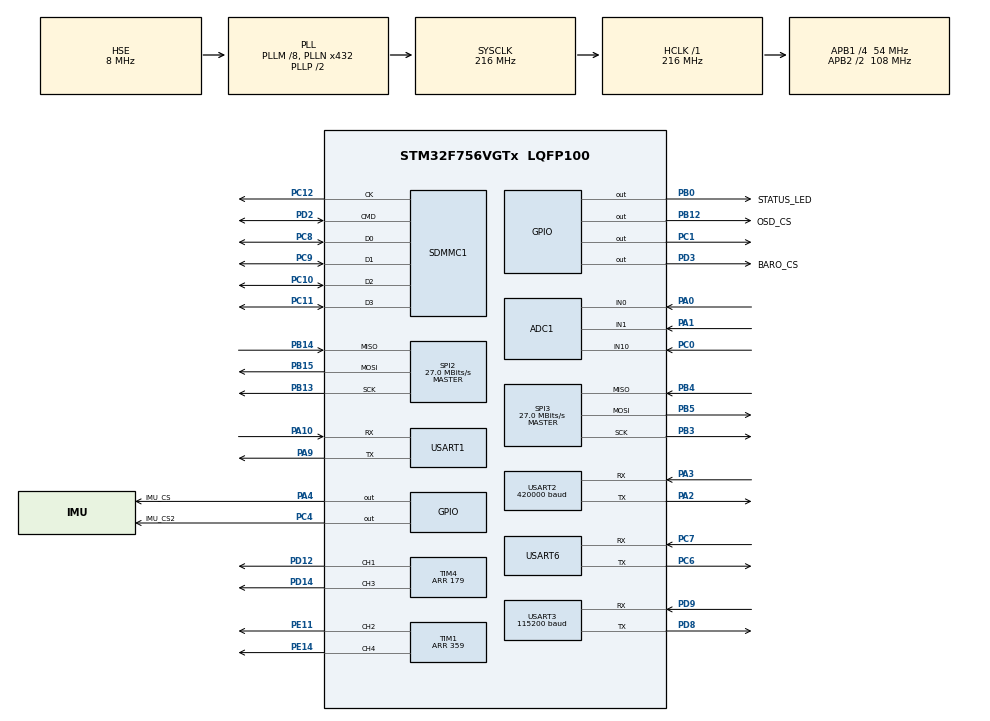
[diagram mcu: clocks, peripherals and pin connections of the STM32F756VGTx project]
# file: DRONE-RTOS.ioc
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ADC1.Channel-0\#ChannelRegularConversion=ADC_CHANNEL_0
ADC1.Channel-1\#ChannelRegularConversion=ADC_CHANNEL_1
ADC1.ContinuousConvMode=ENABLE
ADC1.DMAContinuousRequests=ENABLE
ADC1.DiscontinuousConvMode=DISABLE
ADC1.NbrOfConversion=2
ADC1.NbrOfConversionFlag=1
ADC1.Rank-0\#ChannelRegularConversion=1
ADC1.Rank-1\#ChannelRegularConversion=2
ADC1.SamplingTime-0\#ChannelRegularConversion=ADC_SAMPLETIME_56CYCLES
ADC1.SamplingTime-1\#ChannelRegularConversion=ADC_SAMPLETIME_56CYCLES
ADC1.ScanConvMode=ADC_SCAN_ENABLE
ADC1.master=1
CORTEX_M7.default_mode_Activation=1
Dma.ADC1.3.Direction=DMA_PERIPH_TO_MEMORY
Dma.ADC1.3.FIFOMode=DMA_FIFOMODE_DISABLE
Dma.ADC1.3.Instance=DMA2_Stream0
Dma.ADC1.3.MemDataAlignment=DMA_MDATAALIGN_HALFWORD
Dma.ADC1.3.MemInc=DMA_MINC_ENABLE
Dma.ADC1.3.Mode=DMA_CIRCULAR
Dma.ADC1.3.PeriphDataAlignment=DMA_PDATAALIGN_HALFWORD
Dma.ADC1.3.PeriphInc=DMA_PINC_DISABLE
Dma.ADC1.3.Priority=DMA_PRIORITY_MEDIUM
Dma.Request0=USART2_RX
Dma.Request1=TIM1_CH2
Dma.Request10=USART6_RX
Dma.Request11=TIM4_CH1
Dma.Request2=TIM1_CH4/TRIG/COM
Dma.Request3=ADC1
Dma.Request4=SPI2_RX
Dma.Request5=SPI3_RX
Dma.Request6=TIM4_CH3
Dma.Request7=USART3_RX
Dma.Request8=USART6_TX
Dma.Request9=USART2_TX
Dma.SPI2_RX.4.Direction=DMA_PERIPH_TO_MEMORY
Dma.SPI2_RX.4.FIFOMode=DMA_FIFOMODE_DISABLE
Dma.SPI2_RX.4.Instance=DMA1_Stream3
Dma.SPI2_RX.4.MemDataAlignment=DMA_MDATAALIGN_BYTE
Dma.SPI2_RX.4.MemInc=DMA_MINC_ENABLE
Dma.SPI2_RX.4.Mode=DMA_NORMAL
Dma.SPI2_RX.4.PeriphDataAlignment=DMA_PDATAALIGN_BYTE
Dma.SPI2_RX.4.PeriphInc=DMA_PINC_DISABLE
Dma.SPI2_RX.4.Priority=DMA_PRIORITY_LOW
Dma.SPI3_RX.5.Direction=DMA_PERIPH_TO_MEMORY
Dma.SPI3_RX.5.FIFOMode=DMA_FIFOMODE_DISABLE
Dma.SPI3_RX.5.Instance=DMA1_Stream2
Dma.SPI3_RX.5.MemDataAlignment=DMA_MDATAALIGN_BYTE
Dma.SPI3_RX.5.MemInc=DMA_MINC_ENABLE
Dma.SPI3_RX.5.Mode=DMA_CIRCULAR
Dma.SPI3_RX.5.PeriphDataAlignment=DMA_PDATAALIGN_BYTE
Dma.SPI3_RX.5.PeriphInc=DMA_PINC_DISABLE
Dma.SPI3_RX.5.Priority=DMA_PRIORITY_VERY_HIGH
Dma.TIM1_CH2.1.Direction=DMA_MEMORY_TO_PERIPH
Dma.TIM1_CH2.1.FIFOMode=DMA_FIFOMODE_DISABLE
Dma.TIM1_CH2.1.Instance=DMA2_Stream2
Dma.TIM1_CH2.1.MemDataAlignment=DMA_MDATAALIGN_HALFWORD
Dma.TIM1_CH2.1.MemInc=DMA_MINC_ENABLE
Dma.TIM1_CH2.1.Mode=DMA_NORMAL
Dma.TIM1_CH2.1.PeriphDataAlignment=DMA_PDATAALIGN_HALFWORD
Dma.TIM1_CH2.1.PeriphInc=DMA_PINC_DISABLE
Dma.TIM1_CH2.1.Priority=DMA_PRIORITY_VERY_HIGH
Dma.TIM1_CH4/TRIG/COM.2.Direction=DMA_MEMORY_TO_PERIPH
Dma.TIM1_CH4/TRIG/COM.2.FIFOMode=DMA_FIFOMODE_DISABLE
Dma.TIM1_CH4/TRIG/COM.2.Instance=DMA2_Stream4
Dma.TIM1_CH4/TRIG/COM.2.MemDataAlignment=DMA_MDATAALIGN_HALFWORD
Dma.TIM1_CH4/TRIG/COM.2.MemInc=DMA_MINC_ENABLE
Dma.TIM1_CH4/TRIG/COM.2.Mode=DMA_NORMAL
Dma.TIM1_CH4/TRIG/COM.2.PeriphDataAlignment=DMA_PDATAALIGN_HALFWORD
Dma.TIM1_CH4/TRIG/COM.2.PeriphInc=DMA_PINC_DISABLE
Dma.TIM1_CH4/TRIG/COM.2.Priority=DMA_PRIORITY_VERY_HIGH
Dma.TIM4_CH1.11.Direction=DMA_MEMORY_TO_PERIPH
Dma.TIM4_CH1.11.FIFOMode=DMA_FIFOMODE_DISABLE
Dma.TIM4_CH1.11.Instance=DMA1_Stream0
Dma.TIM4_CH1.11.MemDataAlignment=DMA_MDATAALIGN_HALFWORD
Dma.TIM4_CH1.11.MemInc=DMA_MINC_ENABLE
Dma.TIM4_CH1.11.Mode=DMA_NORMAL
Dma.TIM4_CH1.11.PeriphDataAlignment=DMA_PDATAALIGN_HALFWORD
Dma.TIM4_CH1.11.PeriphInc=DMA_PINC_DISABLE
Dma.TIM4_CH1.11.Priority=DMA_PRIORITY_VERY_HIGH
Dma.TIM4_CH3.6.Direction=DMA_MEMORY_TO_PERIPH
Dma.TIM4_CH3.6.FIFOMode=DMA_FIFOMODE_DISABLE
Dma.TIM4_CH3.6.Instance=DMA1_Stream7
Dma.TIM4_CH3.6.MemDataAlignment=DMA_MDATAALIGN_HALFWORD
Dma.TIM4_CH3.6.MemInc=DMA_MINC_ENABLE
Dma.TIM4_CH3.6.Mode=DMA_NORMAL
Dma.TIM4_CH3.6.PeriphDataAlignment=DMA_PDATAALIGN_HALFWORD
Dma.TIM4_CH3.6.PeriphInc=DMA_PINC_DISABLE
Dma.TIM4_CH3.6.Priority=DMA_PRIORITY_VERY_HIGH
Dma.USART2_RX.0.Direction=DMA_PERIPH_TO_MEMORY
Dma.USART2_RX.0.FIFOMode=DMA_FIFOMODE_DISABLE
Dma.USART2_RX.0.Instance=DMA1_Stream5
Dma.USART2_RX.0.MemDataAlignment=DMA_MDATAALIGN_BYTE
Dma.USART2_RX.0.MemInc=DMA_MINC_ENABLE
Dma.USART2_RX.0.Mode=DMA_CIRCULAR
Dma.USART2_RX.0.PeriphDataAlignment=DMA_PDATAALIGN_BYTE
Dma.USART2_RX.0.PeriphInc=DMA_PINC_DISABLE
Dma.USART2_RX.0.Priority=DMA_PRIORITY_HIGH
Dma.USART2_TX.9.Direction=DMA_MEMORY_TO_PERIPH
Dma.USART2_TX.9.FIFOMode=DMA_FIFOMODE_DISABLE
Dma.USART2_TX.9.Instance=DMA1_Stream6
Dma.USART2_TX.9.MemDataAlignment=DMA_MDATAALIGN_BYTE
Dma.USART2_TX.9.MemInc=DMA_MINC_ENABLE
Dma.USART2_TX.9.Mode=DMA_NORMAL
Dma.USART2_TX.9.PeriphDataAlignment=DMA_PDATAALIGN_BYTE
Dma.USART2_TX.9.PeriphInc=DMA_PINC_DISABLE
Dma.USART2_TX.9.Priority=DMA_PRIORITY_LOW
Dma.USART3_RX.7.Direction=DMA_PERIPH_TO_MEMORY
Dma.USART3_RX.7.FIFOMode=DMA_FIFOMODE_DISABLE
Dma.USART3_RX.7.Instance=DMA1_Stream1
Dma.USART3_RX.7.MemDataAlignment=DMA_MDATAALIGN_BYTE
Dma.USART3_RX.7.MemInc=DMA_MINC_ENABLE
Dma.USART3_RX.7.Mode=DMA_CIRCULAR
Dma.USART3_RX.7.PeriphDataAlignment=DMA_PDATAALIGN_BYTE
Dma.USART3_RX.7.PeriphInc=DMA_PINC_DISABLE
Dma.USART3_RX.7.Priority=DMA_PRIORITY_LOW
Dma.USART6_RX.10.Direction=DMA_PERIPH_TO_MEMORY
Dma.USART6_RX.10.FIFOMode=DMA_FIFOMODE_DISABLE
Dma.USART6_RX.10.Instance=DMA2_Stream1
Dma.USART6_RX.10.MemDataAlignment=DMA_MDATAALIGN_BYTE
Dma.USART6_RX.10.MemInc=DMA_MINC_ENABLE
Dma.USART6_RX.10.Mode=DMA_CIRCULAR
Dma.USART6_RX.10.PeriphDataAlignment=DMA_PDATAALIGN_BYTE
Dma.USART6_RX.10.PeriphInc=DMA_PINC_DISABLE
Dma.USART6_RX.10.Priority=DMA_PRIORITY_MEDIUM
Dma.USART6_TX.8.Direction=DMA_MEMORY_TO_PERIPH
Dma.USART6_TX.8.FIFOMode=DMA_FIFOMODE_DISABLE
Dma.USART6_TX.8.Instance=DMA2_Stream6
Dma.USART6_TX.8.MemDataAlignment=DMA_MDATAALIGN_BYTE
Dma.USART6_TX.8.MemInc=DMA_MINC_ENABLE
Dma.USART6_TX.8.Mode=DMA_NORMAL
Dma.USART6_TX.8.PeriphDataAlignment=DMA_PDATAALIGN_BYTE
Dma.USART6_TX.8.PeriphInc=DMA_PINC_DISABLE
Dma.USART6_TX.8.Priority=DMA_PRIORITY_MEDIUM
Mcu.Family=STM32F7
Mcu.Name=STM32F756VGTx
Mcu.Package=LQFP100
NVIC.DMA1_Stream0_IRQn=true\:0\:0\:false\:false\:true\:false\:true\:true
NVIC.DMA1_Stream1_IRQn=true\:0\:0\:false\:false\:true\:false\:true\:true
NVIC.DMA1_Stream2_IRQn=true\:0\:0\:false\:false\:true\:false\:true\:true
NVIC.DMA1_Stream3_IRQn=true\:0\:0\:false\:false\:true\:false\:true\:true
NVIC.DMA1_Stream5_IRQn=true\:0\:0\:false\:false\:true\:false\:true\:true
NVIC.DMA1_Stream6_IRQn=true\:0\:0\:false\:false\:true\:false\:true\:true
NVIC.DMA1_Stream7_IRQn=true\:0\:0\:false\:false\:true\:false\:true\:true
NVIC.DMA2_Stream0_IRQn=true\:0\:0\:false\:false\:true\:false\:true\:true
NVIC.DMA2_Stream1_IRQn=true\:0\:0\:false\:false\:true\:false\:true\:true
NVIC.DMA2_Stream2_IRQn=true\:0\:0\:false\:false\:true\:false\:true\:true
NVIC.DMA2_Stream4_IRQn=true\:0\:0\:false\:false\:true\:false\:true\:true
NVIC.DMA2_Stream6_IRQn=true\:0\:0\:false\:false\:true\:false\:true\:true
NVIC.PriorityGroup=NVIC_PRIORITYGROUP_4
NVIC.USART1_IRQn=true\:0\:0\:false\:false\:true\:true\:true\:true
NVIC.USART2_IRQn=true\:0\:0\:false\:false\:true\:true\:true\:true
PA0/WKUP.Signal=ADCx_IN0
PA1.Signal=ADCx_IN1
PA10.Mode=Asynchronous
PA10.Signal=USART1_RX
PA13.Mode=Serial_Wire
PA13.Signal=SYS_JTMS-SWDIO
PA14.Mode=Serial_Wire
PA14.Signal=SYS_JTCK-SWCLK
PA2.Mode=Asynchronous
PA2.Signal=USART2_TX
PA3.Mode=Asynchronous
PA3.Signal=USART2_RX
PA4.GPIO_Label=IMU_CS
PA4.GPIO_Speed=GPIO_SPEED_FREQ_VERY_HIGH
PA4.PinState=GPIO_PIN_SET
PA4.Signal=GPIO_Output
PA9.Mode=Asynchronous
PA9.Signal=USART1_TX
PB0.GPIO_Label=STATUS_LED
PB0.GPIO_Speed=GPIO_SPEED_FREQ_VERY_HIGH
PB0.Signal=GPIO_Output
PB12.GPIO_Label=OSD_CS
PB12.GPIO_Speed=GPIO_SPEED_FREQ_VERY_HIGH
PB12.PinState=GPIO_PIN_SET
PB12.Signal=GPIO_Output
PB13.Mode=Full_Duplex_Master
PB13.Signal=SPI2_SCK
PB14.Mode=Full_Duplex_Master
PB14.Signal=SPI2_MISO
PB15.Mode=Full_Duplex_Master
PB15.Signal=SPI2_MOSI
PB3.Mode=Full_Duplex_Master
PB3.Signal=SPI3_SCK
PB4.Mode=Full_Duplex_Master
PB4.Signal=SPI3_MISO
PB5.Mode=Full_Duplex_Master
PB5.Signal=SPI3_MOSI
PC0.Signal=ADCx_IN10
PC1.Signal=GPIO_Output
PC10.GPIO_PuPd=GPIO_PULLUP
PC10.Mode=SD_4_bits_Wide_bus
PC10.Signal=SDMMC1_D2
PC11.GPIO_PuPd=GPIO_PULLUP
PC11.Mode=SD_4_bits_Wide_bus
PC11.Signal=SDMMC1_D3
PC12.Mode=SD_4_bits_Wide_bus
PC12.Signal=SDMMC1_CK
PC4.GPIO_Label=IMU_CS2
PC4.GPIO_Speed=GPIO_SPEED_FREQ_VERY_HIGH
PC4.PinState=GPIO_PIN_SET
PC4.Signal=GPIO_Output
PC6.Mode=Asynchronous
PC6.Signal=USART6_TX
PC7.Mode=Asynchronous
PC7.Signal=USART6_RX
PC8.GPIO_PuPd=GPIO_PULLUP
PC8.Mode=SD_4_bits_Wide_bus
PC8.Signal=SDMMC1_D0
PC9.GPIO_PuPd=GPIO_PULLUP
PC9.Mode=SD_4_bits_Wide_bus
PC9.Signal=SDMMC1_D1
PD12.Signal=S_TIM4_CH1
PD14.Signal=S_TIM4_CH3
PD2.GPIO_PuPd=GPIO_PULLUP
PD2.Mode=SD_4_bits_Wide_bus
PD2.Signal=SDMMC1_CMD
PD3.GPIO_Label=BARO_CS
PD3.GPIO_Speed=GPIO_SPEED_FREQ_VERY_HIGH
PD3.PinState=GPIO_PIN_SET
PD3.Signal=GPIO_Output
PD8.Mode=Asynchronous
PD8.Signal=USART3_TX
PD9.Mode=Asynchronous
PD9.Signal=USART3_RX
PE11.Signal=S_TIM1_CH2
PE14.Signal=S_TIM1_CH4
PH0/OSC_IN.Mode=HSE-External-Oscillator
PH0/OSC_IN.Signal=RCC_OSC_IN
PH1/OSC_OUT.Mode=HSE-External-Oscillator
PH1/OSC_OUT.Signal=RCC_OSC_OUT
ProjectManager.HeapSize=0x200
ProjectManager.StackSize=0x400
ProjectManager.TargetToolchain=CMake
RCC.AHBFreq_Value=216000000
RCC.APB1CLKDivider=RCC_HCLK_DIV4
RCC.APB1Freq_Value=54000000
RCC.APB1TimFreq_Value=108000000
RCC.APB2CLKDivider=RCC_HCLK_DIV2
RCC.APB2Freq_Value=108000000
RCC.APB2TimFreq_Value=216000000
RCC.CortexFreq_Value=216000000
RCC.HCLKFreq_Value=216000000
RCC.HSE_VALUE=8000000
RCC.HSI_VALUE=16000000
RCC.LSE_VALUE=32768
RCC.PLLM=8
RCC.PLLN=432
RCC.PLLQ=9
RCC.PLLSourceVirtual=RCC_PLLSOURCE_HSE
RCC.SDMMCClockSelection=RCC_SDMMC1CLKSOURCE_CLK48
RCC.SYSCLKFreq_VALUE=216000000
RCC.SYSCLKSource=RCC_SYSCLKSOURCE_PLLCLK
RCC.USBFreq_Value=48000000
RCC.VCOOutputFreq_Value=432000000
SDMMC1.ClockBypass=SDMMC_CLOCK_BYPASS_DISABLE
SH.ADCx_IN0.0=ADC1_IN0,IN0
SH.ADCx_IN1.0=ADC1_IN1,IN1
SH.ADCx_IN10.0=ADC1_IN10,IN10
SH.S_TIM1_CH2.0=TIM1_CH2,PWM Generation2 CH2
SH.S_TIM1_CH4.0=TIM1_CH4,PWM Generation4 CH4
SH.S_TIM4_CH1.0=TIM4_CH1,PWM Generation1 CH1
SH.S_TIM4_CH3.0=TIM4_CH3,PWM Generation3 CH3
SPI2.BaudRatePrescaler=SPI_BAUDRATEPRESCALER_2
SPI2.CalculateBaudRate=27.0 MBits/s
SPI2.DataSize=SPI_DATASIZE_8BIT
SPI2.Direction=SPI_DIRECTION_2LINES
SPI2.Mode=SPI_MODE_MASTER
SPI2.VirtualType=VM_MASTER
SPI3.CalculateBaudRate=27.0 MBits/s
SPI3.Direction=SPI_DIRECTION_2LINES
SPI3.Mode=SPI_MODE_MASTER
SPI3.VirtualType=VM_MASTER
TIM1.Channel-PWM\ Generation2\ CH2=TIM_CHANNEL_2
TIM1.Channel-PWM\ Generation4\ CH4=TIM_CHANNEL_4
TIM1.Period=359
TIM4.Channel-PWM\ Generation1\ CH1=TIM_CHANNEL_1
TIM4.Channel-PWM\ Generation3\ CH3=TIM_CHANNEL_3
TIM4.Period=179
USART1.VirtualMode-Asynchronous=VM_ASYNC
USART2.BaudRate=420000
USART2.VirtualMode-Asynchronous=VM_ASYNC
USART3.BaudRate=115200
USART3.VirtualMode-Asynchronous=VM_ASYNC
USART6.VirtualMode=VM_ASYNC
VP_FATFS_VS_Generic.Mode=User_defined
VP_TIM1_VS_ClockSourceINT.Mode=Internal
VP_TIM4_VS_ClockSourceINT.Mode=Internal
board=custom

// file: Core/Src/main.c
/* USER CODE BEGIN Header */
/**
  ******************************************************************************
  * @file           : main.c
  * @brief          : Main program body
  ******************************************************************************
  * @attention
  *
  * Copyright (c) 2026 STMicroelectronics.
  * All rights reserved.
  *
  * This software is licensed under terms that can be found in the LICENSE file
  * in the root directory of this software component.
  * If no LICENSE file comes with this software, it is provided AS-IS.
  *
  ******************************************************************************
  */
/* USER CODE END Header */
#include "main.h"
#include "adc.h"
#include "dma.h"
#include "fatfs.h"
#include "sdmmc.h"
#include "spi.h"
#include "tim.h"
#include "usart.h"
#include "gpio.h"

/* USER CODE BEGIN Includes */
#include "../../src/rtos/rtos.h"
/* USER CODE END Includes */

void SystemClock_Config(void);
static void MPU_Config(void);

int main(void)
{

  /* USER CODE BEGIN 1 */

  start_drone_rtos();

  /* USER CODE END 1 */

  /* MPU Configuration--------------------------------------------------------*/
  MPU_Config();

  /* MCU Configuration--------------------------------------------------------*/

  /* Reset of all peripherals, Initializes the Flash interface and the Systick. */
  HAL_Init();

  /* Configure the system clock */
  SystemClock_Config();

  /* Initialize all configured peripherals */
  MX_GPIO_Init();
  MX_DMA_Init();
  MX_USART1_UART_Init();
  MX_USART2_UART_Init();
  MX_ADC1_Init();
  MX_SPI2_Init();
  MX_TIM1_Init();
  MX_USART3_UART_Init();
  MX_SPI3_Init();
  MX_SDMMC1_SD_Init();
  MX_FATFS_Init();
  MX_TIM4_Init();
  MX_USART6_UART_Init();

  /* Infinite loop */
  while (1)
  {

  }
}

void SystemClock_Config(void)
{
  RCC_OscInitTypeDef RCC_OscInitStruct = {0};
  RCC_ClkInitTypeDef RCC_ClkInitStruct = {0};

  /** Configure the main internal regulator output voltage
  */
  __HAL_RCC_PWR_CLK_ENABLE();
  __HAL_PWR_VOLTAGESCALING_CONFIG(PWR_REGULATOR_VOLTAGE_SCALE1);

  /** Initializes the RCC Oscillators according to the specified parameters
  * in the RCC_OscInitTypeDef structure.
  */
  RCC_OscInitStruct.OscillatorType = RCC_OSCILLATORTYPE_HSE;
  RCC_OscInitStruct.HSEState = RCC_HSE_ON;
  RCC_OscInitStruct.PLL.PLLState = RCC_PLL_ON;
  RCC_OscInitStruct.PLL.PLLSource = RCC_PLLSOURCE_HSE;
  RCC_OscInitStruct.PLL.PLLM = 8;
  RCC_OscInitStruct.PLL.PLLN = 432;
  RCC_OscInitStruct.PLL.PLLP = RCC_PLLP_DIV2;
  RCC_OscInitStruct.PLL.PLLQ = 9;
  if (HAL_RCC_OscConfig(&RCC_OscInitStruct) != HAL_OK)
  {
    Error_Handler();
  }

  /** Activate the Over-Drive mode
  */
  if (HAL_PWREx_EnableOverDrive() != HAL_OK)
  {
    Error_Handler();
  }

  /** Initializes the CPU, AHB and APB buses clocks
  */
  RCC_ClkInitStruct.ClockType = RCC_CLOCKTYPE_HCLK|RCC_CLOCKTYPE_SYSCLK
                              |RCC_CLOCKTYPE_PCLK1|RCC_CLOCKTYPE_PCLK2;
  RCC_ClkInitStruct.SYSCLKSource = RCC_SYSCLKSOURCE_PLLCLK;
  RCC_ClkInitStruct.AHBCLKDivider = RCC_SYSCLK_DIV1;
  RCC_ClkInitStruct.APB1CLKDivider = RCC_HCLK_DIV4;
  RCC_ClkInitStruct.APB2CLKDivider = RCC_HCLK_DIV2;

  if (HAL_RCC_ClockConfig(&RCC_ClkInitStruct, FLASH_LATENCY_7) != HAL_OK)
  {
    Error_Handler();
  }
}

 /* MPU Configuration */

void MPU_Config(void)
{
  MPU_Region_InitTypeDef MPU_InitStruct = {0};

  /* Disables the MPU */
  HAL_MPU_Disable();

  /** Initializes and configures the Region and the memory to be protected
  */
  MPU_InitStruct.Enable = MPU_REGION_ENABLE;
  MPU_InitStruct.Number = MPU_REGION_NUMBER0;
  MPU_InitStruct.BaseAddress = 0x0;
  MPU_InitStruct.Size = MPU_REGION_SIZE_4GB;
  MPU_InitStruct.SubRegionDisable = 0x87;
  MPU_InitStruct.TypeExtField = MPU_TEX_LEVEL0;
  MPU_InitStruct.AccessPermission = MPU_REGION_NO_ACCESS;
  MPU_InitStruct.DisableExec = MPU_INSTRUCTION_ACCESS_DISABLE;
  MPU_InitStruct.IsShareable = MPU_ACCESS_SHAREABLE;
  MPU_InitStruct.IsCacheable = MPU_ACCESS_NOT_CACHEABLE;
  MPU_InitStruct.IsBufferable = MPU_ACCESS_NOT_BUFFERABLE;

  HAL_MPU_ConfigRegion(&MPU_InitStruct);
  /* Enables the MPU */
  HAL_MPU_Enable(MPU_PRIVILEGED_DEFAULT);

}

void Error_Handler(void)
{
  __disable_irq();
  while (1)
  {
  }
}
